# MKV10Z1287 register map
Vendor: Freescale Semiconductor, Inc.; Series: Kinetis_V; File version: 1.6
CPU: CM0PLUS r0p0, little endian, no MPU, no FPU, VTOR, 2 interrupt priority bits
Registers are 32-bit, read-write, reset 0x0 unless marked. A register's access mark holds for its fields unless they carry their own. Offsets are from the block's base; [hi:lo] are bit positions; {n}, {i} and the like mark numbered series; 'fields as' and 'values as' point back to an identical list.

## SIM — System Integration Module
Base 0x40047000; register names take the prefix SIM_
0x00 SOPT1 — System Options Register 1
  [19:18] OSC32KSEL — 32K Oscillator Clock Select
    0=System oscillator (OSC32KCLK); 3=LPO 1 kHz
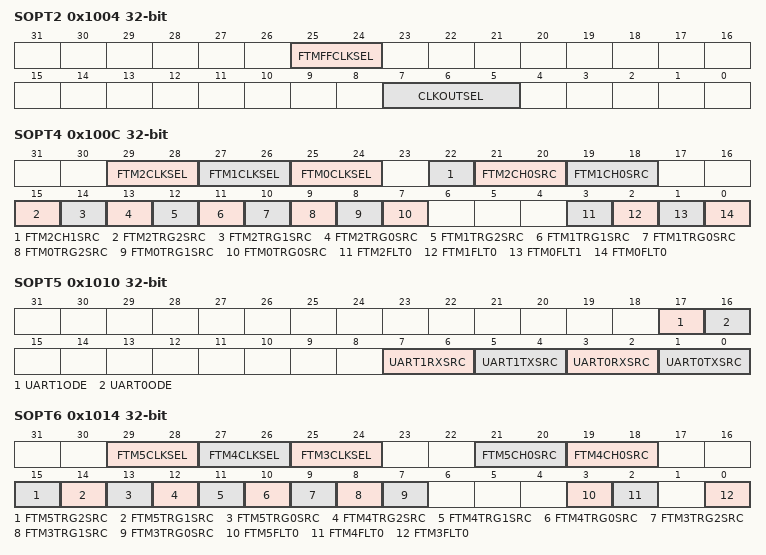
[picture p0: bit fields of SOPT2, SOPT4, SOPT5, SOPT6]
0x1004 SOPT2 — System Options Register 2
  [25:24] FTMFFCLKSEL — FTM Fixed Frequency Clock Select
    0=MCGFFCLK; 1=MCGIRCLK; 2=OSCERCLK; 3=MCGFFCLK
  [7:5] CLKOUTSEL — CLKOUT Select
    2=Bus clock; 3=LPO clock (1 kHz); 4=MCGIRCLK; 6=OSCERCLK
0x100C SOPT4 — System Options Register 4
  [29:28] FTM2CLKSEL — FTM2 External Clock Pin Select
    0=FTM2 external clock driven by FTM_CLKIN0 pin; 1=FTM2 external clock driven by FTM_CLKIN1 pin; 2=FTM2 external clock driven by FTM_CLKIN2 pin
  [27:26] FTM1CLKSEL — FTM1 External Clock Pin Select
    0=FTM1 external clock driven by FTM_CLKIN0 pin; 1=FTM1 external clock driven by FTM_CLKIN1 pin; 2=FTM1 external clock driven by FTM_CLKIN2 pin
  [25:24] FTM0CLKSEL — FTM0 External Clock Pin Select
    0=FTM0 external clock driven by FTM_CLKIN0 pin; 1=FTM0 external clock driven by FTM_CLKIN1 pin; 2=FTM0 external clock driven by FTM_CLKIN2 pin
  [22] FTM2CH1SRC — FTM2 Channel 1 Input Capture Source Select
    0=FTM2_CH1 pin is fed to FTM2 CH1; 1=FTM2_CH1 pin XOR FTM2_CH0 pin XOR FTM1_CH1 pin is fed to FTM2 CH1 If this field is set, then the three input pins feed FTM2 channel 1 input capture. In this case, FTM1 channel 1 cannot be used for input capture of FTM1, as it has no pin. FTM1 channel1 can be used for Output Compare mode of FTM1, though without an output.
  [21:20] FTM2CH0SRC — FTM2 Channel 0 Input Capture Source Select
    0=FTM2_CH0 signal; 1=CMP0 output; 2=CMP1 output
  [19:18] FTM1CH0SRC — FTM1 Channel 0 Input Capture Source Select
    0=FTM1_CH0 signal; 1=CMP0 output; 2=CMP1 output
  [15] FTM2TRG2SRC — FlexTimer 2 Hardware Trigger 2 Source Select
    0=CMP0 output drives FTM2 hardware trigger 2; 1=CMP1 output drives FTM2 hardware trigger 2
  [14] FTM2TRG1SRC — FlexTimer 2 Hardware Trigger 1 Source Select
    0=PDB0 output trigger 1 drives FTM2 hardware trigger 1; 1=FTM1 channel match drives FTM2 hardware trigger 1
  [13] FTM2TRG0SRC — FlexTimer 2 Hardware Trigger 0 Source Select
    0=CMP0 output drives FTM2 hardware trigger 0; 1=FTM0 channel match drives FTM2 hardware trigger 0
  [12] FTM1TRG2SRC — FlexTimer 1 Hardware Trigger 2 Source Select
    0=CMP0 output drives FTM1 hardware trigger 2; 1=CMP1 output drives FTM1 hardware trigger 2
  [11] FTM1TRG1SRC — FlexTimer 1 Hardware Trigger 1 Source Select
    0=PDB0 channel 1 trigger drives FTM1 hardware trigger 1; 1=FTM2 channel match drives FTM1 hardware trigger 1
  [10] FTM1TRG0SRC — FlexTimer 1 Hardware Trigger 0 Source Select
    0=CMP0 output drives FTM1 hardware trigger 0; 1=FTM0 channel match drives FTM1 hardware trigger 0
  [9] FTM0TRG2SRC — FlexTimer 0 Hardware Trigger 2 Source Select
    0=CMP0 output drives FTM0 hardware trigger 2; 1=CMP1 output drives FTM0 hardware trigger 2
  [8] FTM0TRG1SRC — FlexTimer 0 Hardware Trigger 1 Source Select
    0=PDB0 channel 1 trigger drives FTM0 hardware trigger 1; 1=FTM2 channel match drives FTM0 hardware trigger 1
  [7] FTM0TRG0SRC — FlexTimer 0 Hardware Trigger 0 Source Select
    0=CMP0 output drives FTM0 hardware trigger 0; 1=FTM1 channel match drives FTM0 hardware trigger 0
  [3] FTM2FLT0 — FTM2 Fault 0 Select
    0=FTM2_FLT0 pin; 1=CMP0 out
  [2] FTM1FLT0 — FTM1 Fault 0 Select
    0=FTM1_FLT0 pin; 1=CMP0 out
  [1] FTM0FLT1 — FTM0 Fault 1 Select
    0=FTM0_FLT1 pin; 1=CMP1 out
  [0] FTM0FLT0 — FTM0 Fault 0 Select
    0=FTM0_FLT0 pin; 1=CMP0 out
0x1010 SOPT5 — System Options Register 5
  [17] UART1ODE — UART1 Open Drain Enable
    0=Open drain is disabled on UART1; 1=Open drain is enabled on UART1
  [16] UART0ODE — UART0 Open Drain Enable
    0=Open drain is disabled on UART0; 1=Open drain is enabled on UART0
  [7:6] UART1RXSRC — UART 1 Receive Data Source Select
    0=UART1_RX pin; 1=CMP0; 2=CMP1
  [5:4] UART1TXSRC — UART 1 Transmit Data Source Select
    0=UART1_TX pin; 1=UART1_TX pin modulated with FTM1 channel 0 output; 2=UART1_TX pin modulated with FTM2 channel 0 output
  [3:2] UART0RXSRC — UART 0 Receive Data Source Select
    0=UART0_RX pin; 1=CMP0; 2=CMP1
  [1:0] UART0TXSRC — UART 0 Transmit Data Source Select
    0=UART0_TX pin; 1=UART0_TX pin modulated with FTM1 channel 0 output; 2=UART0_TX pin modulated with FTM2 channel 0 output
0x1014 SOPT6 — Systems Option Register 6
  [29:28] FTM5CLKSEL — FTM5 External Clock Pin Select
    0=FTM5 external clock driven by FTM_CLKIN0 pin; 1=FTM5 external clock driven by FTM_CLKIN1 pin; 2=FTM5 external clock driven by FTM_CLKIN2 pin
  [27:26] FTM4CLKSEL — FTM4 External Clock Pin Select
    0=FTM4 external clock driven by FTM_CLKIN0 pin; 1=FTM4 external clock driven by FTM_CLKIN1 pin; 2=FTM4 external clock driven by FTM_CLKIN2 pin
  [25:24] FTM3CLKSEL — FTM3 External Clock Pin Select
    0=FTM3 external clock driven by FTM_CLKIN0 pin; 1=FTM3 external clock driven by FTM_CLKIN1 pin; 2=FTM3 external clock driven by FTM_CLKIN2 pin
  [21:20] FTM5CH0SRC — FTM5 channel 0 input capture source select
    0=FTM5_CH0 signal; 1=CMP0 output; 2=CMP1 output
  [19:18] FTM4CH0SRC — FTM4 channel 0 input capture source select
    0=FTM4_CH0 signal; 1=CMP0 output; 2=CMP1 output
  [15] FTM5TRG2SRC — FlexTimer 5 Hardware Trigger 2 Source Select
    0=CMP0 output drives FTM5 hardware trigger 2; 1=CMP1 output drives FTM5 hardware trigger 2
  [14] FTM5TRG1SRC — FlexTimer 5 Hardware Trigger 1 Source Select
    0=PDB1 output trigger 1 drives FTM5 hardware trigger 1; 1=FTM4 channel match drives FTM5 hardware trigger 1
  [13] FTM5TRG0SRC — FlexTimer 5 Hardware Trigger 0 Source Select
    0=CMP0 output drives FTM5 hardware trigger 0; 1=FTM3 channel match drives FTM5 hardware trigger 0
  [12] FTM4TRG2SRC — FlexTimer 4 Hardware Trigger 2 Source Select
    0=CMP0 output drives FTM4 hardware trigger 2; 1=CMP1 output drives FTM4 hardware trigger 2
  [11] FTM4TRG1SRC — FlexTimer 4 Hardware Trigger 1 Source Select
    0=PDB1 output trigger 1 drives FTM4 hardware trigger 1; 1=FTM5 channel match drives FTM4 hardware trigger 1
  [10] FTM4TRG0SRC — FlexTimer 4 Hardware Trigger 0 Source Select
    0=CMP0 output drives FTM4 hardware trigger 0; 1=FTM3 channel match drives FTM4 hardware trigger 0
  [9] FTM3TRG2SRC — FlexTimer 3 Hardware Trigger 2 Source Select
    0=CMP0 output drives FTM3 hardware trigger 2; 1=CMP1 output drives FTM3 hardware trigger 2
  [8] FTM3TRG1SRC — FlexTimer 3 Hardware Trigger 1 Source Select
    0=PDB1 output drives FTM3 hardware trigger 1; 1=FTM4 channel match drives FTM3 hardware trigger 1
  [7] FTM3TRG0SRC — FlexTimer 3 Hardware Trigger 0 Source Select
    0=CMP0 output drives FTM3 hardware trigger 0; 1=FTM5 channel match drives FTM3 hardware trigger 0
  [3] FTM5FLT0 — FTM5 Fault 0 Select
    0=FTM5_FLT0 pin; 1=CMP0 out
  [2] FTM4FLT0 — FTM4 Fault 0 Select
    0=FTM4_FLT0 pin; 1=CMP0 out
  [0] FTM3FLT0 — FTM3 Fault 0 Select
    0=FTM3_FLT0 pin; 1=CMP0 out
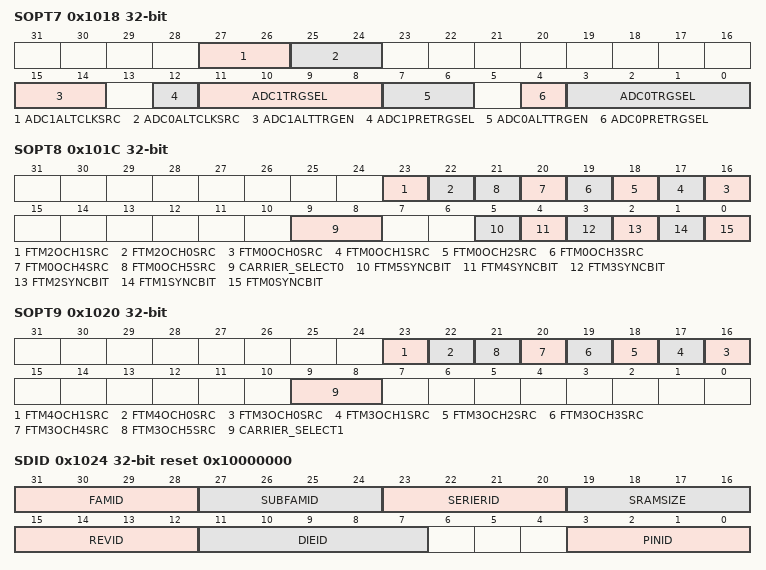
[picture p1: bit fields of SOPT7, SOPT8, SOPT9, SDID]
0x1018 SOPT7 — System Options Register 7
  [27:26] ADC1ALTCLKSRC — ADC1 ALT Clock Source Select
    0=OUTDIV5 output; 1=MCGIRCLK; 2=OSCERCLK
  [25:24] ADC0ALTCLKSRC — ADC0 ALT Clock Source Select
    0=OUTDIV5 output; 1=MCGIRCLK; 2=OSCERCLK
  [15:14] ADC1ALTTRGEN — Enable alternative conversion triggers for ADC1.
    0=PDB0 CH1 triggers ADC1; 1=PDB1 CH1 triggers ADC1; 2=Alt trigger source ADC1TRGSEL; 3=PDB0 CH1 OR PDB1 CH1 trigger ADC1
  [12] ADC1PRETRGSEL — ADC1 Pre-trigger Select
    0=Pre-trigger A for ADC1. Clearing this field will result in ADHWTSA=1 and ADHWTSB=0.; 1=Pre-trigger B for ADC1. Setting this bit will result in ADHWTSA=0 and ADHWTSB=1.
  [11:8] ADC1TRGSEL — ADC1 Trigger Select
    0=External trigger pin input (PDB_EXTRG0); 1=CMP0 output; 2=CMP1 output; 3=External trigger pin input (PDB_EXTRG1); {v}=DMA channel {v-4} transfer last write complete (v=4..7); 8=FTM0 intialtrig or external trig output; {v}=FTM{v-8} intial trig or external trig output (v=9..13); 14=LPTMR0 trigger
  [7:6] ADC0ALTTRGEN — Enable alternative conversion triggers for ADC0.
    0=PDB0 CH0 triggers ADC0; 1=PDB1 CH0 triggers ADC0; 2=Alt trigger source as per ADC0TRGSEL; 3=PDB0 CH0 OR PDB1 CH0 trigger ADC0
  [4] ADC0PRETRGSEL — ADC0 Pre-trigger Select
    0=Pre-trigger A for ADC0. Clearing this field will result in ADHWTSA=1 and ADHWTSB=0.; 1=Pre-trigger B for ADC0. Setting this bit will result in ADHWTSA=0 and ADHWTSB=1.
  [3:0] ADC0TRGSEL — ADC0 Trigger Select
    values as ADC1TRGSEL
0x101C SOPT8 — System Options Register 8
  [23] FTM2OCH1SRC — FTM2 channel 1 output PWM/OCMP mode source select
    0=FTM2CH1 pin is the output of FTM2 channel 1 PWM/OCMP; 1=FTM2CH1 pin is the output of FTM2 channel 1 PWM/OCMP modulating the carrier frequency, as per CARRIER_SELECT0
  [22] FTM2OCH0SRC — FTM2 channel 0 output PWM/OCMP mode source select
    0=FTM2CH0 pin is the output of FTM2 channel 0 PWM/OCMP; 1=FTM2CH0 pin is the output of FTM2 channel 0 PWM/OCMP modulating the carrier frequency, as per CARRIER_SELECT0
  [n+16] FTM0OCH{n}SRC (n=0..5) — FTM0 channel {n} output PWM/OCMP mode source select
    0=FTM0CH{n} pin is the output of FTM0 channel {n} PWM/OCMP; 1=FTM0CH{n} pin is the output of FTM0 channel {n} PWM/OCMP modulating the carrier frequency, as per CARRIER_SELECT0
  [9:8] CARRIER_SELECT0 — Carrier frequency selection for FTM0/2 output channel
    0=FTM1_CH1 output provides the carrier signal for Timer Modulation mode; 1=LPTMR0 prescaler output provides the carrier signal for Timer Modulation mode; 2=FTM5_CH1 output provides the carrier signal for Timer Modulation mode
  [5] FTM5SYNCBIT — FlexTimer 5 Hardware Trigger 0 configure by software
    0=No effect on FTM5; this allows the hardware trigger options to function as expected. See SOPT6[FTM5TRG0SRC].; 1=If TRIG0 is enabled, this refreshes the FTM5CNTIN and allbuffered registers of the FTM5 (must write 0 first then write 1); this masks the hardware trigger
  [4] FTM4SYNCBIT — FlexTimer 4 Hardware Trigger 0 configure by software
    0=No effect to FTM4; this allows the hardware trigger options to function as expected. See SOPT6[FTM4TRG0SRC].; 1=If TRIG0 is enabled, this refreshes the FTM4CNTIN and allbuffered registers of the FTM4 (must write 0 first then write 1); this masks the hardware trigger
  [3] FTM3SYNCBIT — FlexTimer 3 Hardware Trigger 0 configure by software
    0=No effect to FTM3; this allows the hardware trigger options to function as expected. See SOPT6[FTM3TRG0SRC].; 1=If TRIG0 is enabled, this refreshes the FTM3CNTIN and allbuffered registers of the FTM3 (must write 0 first then write 1); this masks the hardware trigger
  [2] FTM2SYNCBIT — FlexTimer 2 Hardware Trigger 0 configure by software
    0=No effect to FTM2; this allows the hardware trigger options to function as expected. See SOPT4[FTM2TRG0SRC].; 1=If TRIG0 is enabled, this refreshes the FTM2CNTIN and all buffered registers of the FTM2 (must write 0 first then write 1); this masks the hardware trigger
  [1] FTM1SYNCBIT — FlexTimer 1 Hardware Trigger 0 configure by software
    0=No effect to FTM1; this allows the hardware trigger options to function as expected. See SOPT4[FTM1TRG0SRC].; 1=If TRIG0 enabled, this refreshes the FTM1CNTIN and all buffered registers of the FTM1 (must write 0 first then write 1); this masks the hardware trigger
  [0] FTM0SYNCBIT — FlexTimer 0 Hardware Trigger 0 configure by software
    0=No effect to FTM0; this allow the hardware trigger options to function as expected. See SOPT4[FTM0TRG0SRC].; 1=If TRIG0 enabled, this refreshes the FTM0CNTIN and all buffered registers of the FTM0 (must write 0 first then write 1); this masks the hardware trigger
0x1020 SOPT9 — System Options Register 9
  [23] FTM4OCH1SRC — FTM4 channel 1 output PWM/OCMP mode source select
    0=FTM4CH1 pin is the output of FTM4 channel 1 PWM/OCMP; 1=FTM4CH1 pin is the output of FTM4 channel 1 PWM/OCMP modulating the carrier frequency, as per CARRIER_SELECT1
  [22] FTM4OCH0SRC — FTM4 channel 0 output PWM/OCMP mode source select
    0=FTM4CH0 pin is the output of FTM4 channel 0 PWM/OCMP; 1=FTM4CH0 pin is the output of FTM4 channel 0 PWM/OCMP modulating the carrier frequency, as per CARRIER_SELECT1
  [n+16] FTM3OCH{n}SRC (n=0..5) — FTM3 channel {n} output PWM/OCMP mode source select
    0=FTM3CH{n} pin is the output of FTM3 channel {n} PWM/OCMP; 1=FTM3CH{n} pin is the output of FTM3 channel {n} PWM/OCMP modulating the carrier frequency, as per CARRIER_SELECT1
  [9:8] CARRIER_SELECT1 — Carrier frequency selection for FTM3/4 output channel
    values as SOPT8.CARRIER_SELECT0
0x1024 SDID ro reset 0x10000000 (reset mask 0xF0000070) — System Device Identification Register
  [31:28] FAMID — V-Family ID
    1=MKV1xZx
  [27:24] SUBFAMID — V Sub-family ID
    0=MKV10xxxx; 1=MKV11xxxx
  [23:20] SERIERID — Series ID
    6=V-family - Motor control
  [19:16] SRAMSIZE — Specifies the size of the System SRAM.
    5=16 KB
  [15:12] REVID — Device revision number
  [11:7] DIEID — Device die number
  [3:0] PINID — Pincount identification
    2=32-pin; 4=48-pin; 5=64-pin
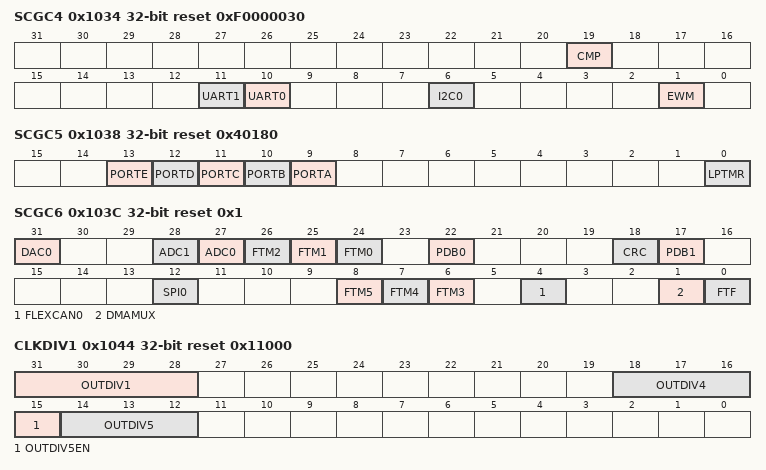
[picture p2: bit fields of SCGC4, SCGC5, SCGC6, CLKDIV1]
0x1034 SCGC4 reset 0xF0000030 — System Clock Gating Control Register 4
  [all] fields
    0=Clock disabled; 1=Clock enabled
  [19] CMP — Comparator Clock Gate Control
  [11] UART1 — UART1 Clock Gate Control
  [10] UART0 — UART0 Clock Gate Control
  [6] I2C0 — I2C0 Clock Gate Control
  [1] EWM — EWM Clock Gate Control
0x1038 SCGC5 reset 0x40180 — System Clock Gating Control Register 5
  [13] PORTE — Port E Clock Gate Control
    0=Clock disabled; 1=Clock enabled
  [12] PORTD — Port D Clock Gate Control
    0=Clock disabled; 1=Clock enabled
  [11] PORTC — Port C Clock Gate Control
    0=Clock disabled; 1=Clock enabled
  [10] PORTB — Port B Clock Gate Control
    0=Clock disabled; 1=Clock enabled
  [9] PORTA — Port A Clock Gate Control
    0=Clock disabled; 1=Clock enabled
  [0] LPTMR — Low Power Timer Clock Gate Control
    0=Access disabled; 1=Access enabled
0x103C SCGC6 reset 0x1 — System Clock Gating Control Register 6
  [all] fields
    0=Clock disabled; 1=Clock enabled
  [31] DAC0 — DAC0 Clock Gate Control
  [28] ADC1 — ADC1 Clock Gate Control
  [27] ADC0 — ADC0 Clock Gate Control
  [26] FTM2 — FTM2 Clock Gate Control
  [25] FTM1 — FTM1 Clock Gate Control
  [24] FTM0 — FTM0 Clock Gate Control
  [22] PDB0 — PDB0 Clock Gate Control
  [18] CRC — CRC Clock Gate Control
  [17] PDB1 — PDB1 Clock Gate Control
  [12] SPI0 — SPI0 Clock Gate Control
  [8] FTM5 — FTM5 Clock Gate Control
  [7] FTM4 — FTM4 Clock Gate Control
  [6] FTM3 — FTM3 Clock Gate Control
  [4] FLEXCAN0 — FLEXCAN0 Clock Gate Control
  [1] DMAMUX — DMA Mux Clock Gate Control
  [0] FTF — Flash Memory Clock Gate Control
0x1040 SCGC7 reset 0x100 — System Clock Gating Control Register 7
  [8] DMA — DMA Clock Gate Control
    0=Clock disabled; 1=Clock enabled
0x1044 CLKDIV1 reset 0x11000 — System Clock Divider Register 1
  [31:28] OUTDIV1 — Clock 1 Output Divider Value
    {v}=Divide-by-{v+1} (v=0..15)
  [18:16] OUTDIV4 — Clock 4 Output Divider Value
    {v}=Divide-by-{v+1} (v=0..7)
  [15] OUTDIV5EN — OUTDIV5 Divider Control
    0=OUTDIV5 disabled; 1=OUTDIV5 enabled
  [14:12] OUTDIV5 — Clock 5 Output Divider Value
    {v}=Divide-by-{v+1} (v=0..7)
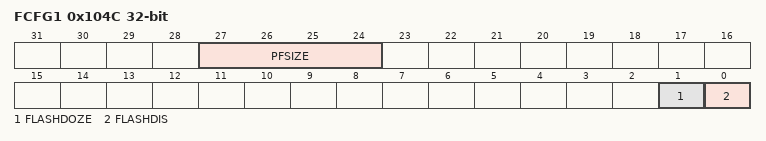
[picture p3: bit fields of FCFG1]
0x104C FCFG1 (reset mask 0xF0FFFFFF) — Flash Configuration Register 1
  [27:24] PFSIZE ro — Program Flash Size
    0=8 KB of program flash memory, 0.25 KB protection region; 1=16 KB of program flash memory, 0.5 KB protection region; 3=32 KB of program flash memory, 1 KB protection region; 5=64 KB of program flash memory, 2 KB protection region; 7=128 KB of program flash memory, 4 KB protection region; 9=256 KB of program flash memory, 4 KB protection region; 15=32 KB of program flash memory, 1 KB protection region
  [1] FLASHDOZE
    0=Flash remains enabled during Doze mode; 1=Flash is disabled for the duration of Doze mode
  [0] FLASHDIS — Flash Disable
    0=Flash is enabled; 1=Flash is disabled
0x1050 FCFG2 ro reset 0x800000 (reset mask 0x80FFFFFF) — Flash Configuration Register 2
  [30:24] MAXADDR — Max address block
0x1058 UIDMH ro reset not defined — Unique Identification Register Mid-High
  [15:0] UID — Unique Identification
0x105C UIDML ro reset not defined — Unique Identification Register Mid Low
  [31:0] UID — Unique Identification
0x1060 UIDL ro reset not defined — Unique Identification Register Low
  [31:0] UID — Unique Identification
0x1100 WDOGC — WDOG Control Register
  [1] WDOGCLKS — WDOG Clock Select
    0=Internal 1 kHz clock is source to WDOG; 1=MCGIRCLK is source to WDOG

## Notices in the file
Redistribution and use in source and binary forms, with or without modification,
are permitted provided that the following conditions are met:
o Redistributions of source code must retain the above copyright notice, this list
of conditions and the following disclaimer.
o Redistributions in binary form must reproduce the above copyright notice, this
list of conditions and the following disclaimer in the documentation and/or
other materials provided with the distribution.
o Neither the name of Freescale Semiconductor, Inc. nor the names of its
contributors may be used to endorse or promote products derived from this
software without specific prior written permission.
THIS SOFTWARE IS PROVIDED BY THE COPYRIGHT HOLDERS AND CONTRIBUTORS "AS IS" AND
ANY EXPRESS OR IMPLIED WARRANTIES, INCLUDING, BUT NOT LIMITED TO, THE IMPLIED
WARRANTIES OF MERCHANTABILITY AND FITNESS FOR A PARTICULAR PURPOSE ARE
DISCLAIMED. IN NO EVENT SHALL THE COPYRIGHT HOLDER OR CONTRIBUTORS BE LIABLE FOR
ANY DIRECT, INDIRECT, INCIDENTAL, SPECIAL, EXEMPLARY, OR CONSEQUENTIAL DAMAGES
(INCLUDING, BUT NOT LIMITED TO, PROCUREMENT OF SUBSTITUTE GOODS OR SERVICES;
LOSS OF USE, DATA, OR PROFITS; OR BUSINESS INTERRUPTION) HOWEVER CAUSED AND ON
ANY THEORY OF LIABILITY, WHETHER IN CONTRACT, STRICT LIABILITY, OR TORT
(INCLUDING NEGLIGENCE OR OTHERWISE) ARISING IN ANY WAY OUT OF THE USE OF THIS
SOFTWARE, EVEN IF ADVISED OF THE POSSIBILITY OF SUCH DAMAGE.
